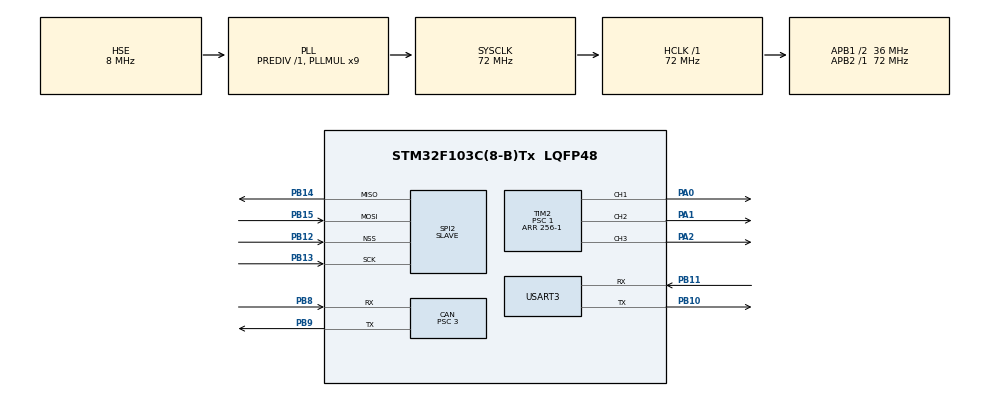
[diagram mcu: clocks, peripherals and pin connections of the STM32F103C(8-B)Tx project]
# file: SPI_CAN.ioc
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CAN.BS1=CAN_BS1_3TQ
CAN.BS2=CAN_BS2_8TQ
CAN.CalculateBaudRate=999999
CAN.CalculateTimeBit=1000
CAN.CalculateTimeQuantum=83.33333333333334
CAN.Prescaler=3
Dma.Request0=SPI2_RX
Dma.Request1=SPI2_TX
Dma.SPI2_RX.0.Direction=DMA_PERIPH_TO_MEMORY
Dma.SPI2_RX.0.Instance=DMA1_Channel4
Dma.SPI2_RX.0.MemDataAlignment=DMA_MDATAALIGN_BYTE
Dma.SPI2_RX.0.MemInc=DMA_MINC_ENABLE
Dma.SPI2_RX.0.Mode=DMA_CIRCULAR
Dma.SPI2_RX.0.PeriphDataAlignment=DMA_PDATAALIGN_BYTE
Dma.SPI2_RX.0.PeriphInc=DMA_PINC_DISABLE
Dma.SPI2_RX.0.Priority=DMA_PRIORITY_LOW
Dma.SPI2_TX.1.Direction=DMA_MEMORY_TO_PERIPH
Dma.SPI2_TX.1.Instance=DMA1_Channel5
Dma.SPI2_TX.1.MemDataAlignment=DMA_MDATAALIGN_BYTE
Dma.SPI2_TX.1.MemInc=DMA_MINC_ENABLE
Dma.SPI2_TX.1.Mode=DMA_CIRCULAR
Dma.SPI2_TX.1.PeriphDataAlignment=DMA_PDATAALIGN_BYTE
Dma.SPI2_TX.1.PeriphInc=DMA_PINC_DISABLE
Dma.SPI2_TX.1.Priority=DMA_PRIORITY_LOW
Mcu.Family=STM32F1
Mcu.Name=STM32F103C(8-B)Tx
Mcu.Package=LQFP48
NVIC.CAN1_RX1_IRQn=true\:0\:0\:false\:false\:true\:true\:true\:true
NVIC.DMA1_Channel4_IRQn=true\:0\:0\:false\:false\:true\:false\:true\:true
NVIC.DMA1_Channel5_IRQn=true\:0\:0\:false\:false\:true\:false\:true\:true
NVIC.PriorityGroup=NVIC_PRIORITYGROUP_4
NVIC.SPI2_IRQn=true\:0\:0\:false\:false\:true\:true\:true\:true
NVIC.USB_LP_CAN1_RX0_IRQn=true\:0\:0\:false\:false\:true\:true\:true\:true
PA0-WKUP.Signal=S_TIM2_CH1_ETR
PA1.Signal=S_TIM2_CH2
PA13.Mode=Serial_Wire
PA13.Signal=SYS_JTMS-SWDIO
PA14.Mode=Serial_Wire
PA14.Signal=SYS_JTCK-SWCLK
PA2.Signal=S_TIM2_CH3
PB10.Mode=Asynchronous
PB10.Signal=USART3_TX
PB11.Mode=Asynchronous
PB11.Signal=USART3_RX
PB12.Mode=NSS_Signal_Hard_Input
PB12.Signal=SPI2_NSS
PB13.Mode=Full_Duplex_Slave
PB13.Signal=SPI2_SCK
PB14.Mode=Full_Duplex_Slave
PB14.Signal=SPI2_MISO
PB15.Mode=Full_Duplex_Slave
PB15.Signal=SPI2_MOSI
PB8.Mode=CAN_Activate
PB8.Signal=CAN_RX
PB9.Mode=CAN_Activate
PB9.Signal=CAN_TX
PD0-OSC_IN.Mode=HSE-External-Oscillator
PD0-OSC_IN.Signal=RCC_OSC_IN
PD1-OSC_OUT.Mode=HSE-External-Oscillator
PD1-OSC_OUT.Signal=RCC_OSC_OUT
ProjectManager.HeapSize=0x200
ProjectManager.StackSize=0x400
ProjectManager.TargetToolchain=STM32CubeIDE
RCC.AHBFreq_Value=72000000
RCC.APB1CLKDivider=RCC_HCLK_DIV2
RCC.APB1Freq_Value=36000000
RCC.APB1TimFreq_Value=72000000
RCC.APB2Freq_Value=72000000
RCC.APB2TimFreq_Value=72000000
RCC.HCLKFreq_Value=72000000
RCC.PLLMUL=RCC_PLL_MUL9
RCC.PLLSourceVirtual=RCC_PLLSOURCE_HSE
RCC.SYSCLKFreq_VALUE=72000000
RCC.SYSCLKSource=RCC_SYSCLKSOURCE_PLLCLK
RCC.USBFreq_Value=72000000
SH.S_TIM2_CH1_ETR.0=TIM2_CH1,PWM Generation1 CH1
SH.S_TIM2_CH2.0=TIM2_CH2,PWM Generation2 CH2
SH.S_TIM2_CH3.0=TIM2_CH3,PWM Generation3 CH3
SPI2.CRCCalculation=SPI_CRCCALCULATION_DISABLE
SPI2.DataSize=SPI_DATASIZE_8BIT
SPI2.Direction=SPI_DIRECTION_2LINES
SPI2.Mode=SPI_MODE_SLAVE
SPI2.VirtualNSS=VM_NSSHARD
SPI2.VirtualType=VM_SLAVE
TIM2.AutoReloadPreload=TIM_AUTORELOAD_PRELOAD_DISABLE
TIM2.Channel-PWM\ Generation1\ CH1=TIM_CHANNEL_1
TIM2.Channel-PWM\ Generation2\ CH2=TIM_CHANNEL_2
TIM2.Channel-PWM\ Generation3\ CH3=TIM_CHANNEL_3
TIM2.OCMode_PWM-PWM\ Generation1\ CH1=TIM_OCMODE_PWM2
TIM2.OCMode_PWM-PWM\ Generation2\ CH2=TIM_OCMODE_PWM2
TIM2.OCMode_PWM-PWM\ Generation3\ CH3=TIM_OCMODE_PWM2
TIM2.Period=256-1
TIM2.Prescaler=1
USART3.VirtualMode=VM_ASYNC
VP_TIM2_VS_ClockSourceINT.Mode=Internal
board=custom

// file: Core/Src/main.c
/* USER CODE BEGIN Header */
/**
  ******************************************************************************
  * @file           : main.c
  * @brief          : Main program body
  ******************************************************************************
  * @attention
  *
  * Copyright (c) 2024 STMicroelectronics.
  * All rights reserved.
  *
  * This software is licensed under terms that can be found in the LICENSE file
  * in the root directory of this software component.
  * If no LICENSE file comes with this software, it is provided AS-IS.
  *
  ******************************************************************************
  */
/* USER CODE END Header */
#include "main.h"
#include "can.h"
#include "dma.h"
#include "spi.h"
#include "tim.h"
#include "usart.h"
#include "gpio.h"

/* USER CODE BEGIN Includes */
#include "common.h"
extern uint8_t spi_tx[BUFFER_SIZE], spi_rx[BUFFER_SIZE];

uint8_t err = HAL_OK;

/* USER CODE END Includes */

void SystemClock_Config(void);

int main(void)
{

  /* MCU Configuration--------------------------------------------------------*/

  /* Reset of all peripherals, Initializes the Flash interface and the Systick. */
  HAL_Init();

  /* Configure the system clock */
  SystemClock_Config();

  /* Initialize all configured peripherals */
  MX_GPIO_Init();
  MX_DMA_Init();
  MX_TIM2_Init();
  MX_SPI2_Init();
  MX_CAN_Init();
  MX_USART3_UART_Init();
  /* USER CODE BEGIN 2 */
  ledInit(&htim2);
  ledSet(20, 20, 40);
  CanInit(&hcan);

//  if((err = HAL_SPI_TransmitReceive_DMA(&hspi2, spi_tx, spi_rx, BUFFER_SIZE)) != HAL_OK) {
//    char fmt[50]; sprintf(fmt, "dma error(%d)\r\n", err);
//    HAL_UART_Transmit(&huart3, (uint8_t *)fmt, strlen(fmt), 0xffff);
//  }
  HAL_SPI_TransmitReceive_DMA(&hspi2, spi_tx, spi_rx, BUFFER_SIZE);
  /* USER CODE END 2 */

  /* Infinite loop */
  while (1)
  {

  }
}

void SystemClock_Config(void)
{
  RCC_OscInitTypeDef RCC_OscInitStruct = {0};
  RCC_ClkInitTypeDef RCC_ClkInitStruct = {0};

  /** Initializes the RCC Oscillators according to the specified parameters
  * in the RCC_OscInitTypeDef structure.
  */
  RCC_OscInitStruct.OscillatorType = RCC_OSCILLATORTYPE_HSE;
  RCC_OscInitStruct.HSEState = RCC_HSE_ON;
  RCC_OscInitStruct.HSEPredivValue = RCC_HSE_PREDIV_DIV1;
  RCC_OscInitStruct.HSIState = RCC_HSI_ON;
  RCC_OscInitStruct.PLL.PLLState = RCC_PLL_ON;
  RCC_OscInitStruct.PLL.PLLSource = RCC_PLLSOURCE_HSE;
  RCC_OscInitStruct.PLL.PLLMUL = RCC_PLL_MUL9;
  if (HAL_RCC_OscConfig(&RCC_OscInitStruct) != HAL_OK)
  {
    Error_Handler();
  }

  /** Initializes the CPU, AHB and APB buses clocks
  */
  RCC_ClkInitStruct.ClockType = RCC_CLOCKTYPE_HCLK|RCC_CLOCKTYPE_SYSCLK
                              |RCC_CLOCKTYPE_PCLK1|RCC_CLOCKTYPE_PCLK2;
  RCC_ClkInitStruct.SYSCLKSource = RCC_SYSCLKSOURCE_PLLCLK;
  RCC_ClkInitStruct.AHBCLKDivider = RCC_SYSCLK_DIV1;
  RCC_ClkInitStruct.APB1CLKDivider = RCC_HCLK_DIV2;
  RCC_ClkInitStruct.APB2CLKDivider = RCC_HCLK_DIV1;

  if (HAL_RCC_ClockConfig(&RCC_ClkInitStruct, FLASH_LATENCY_2) != HAL_OK)
  {
    Error_Handler();
  }
}

void Error_Handler(void)
{
  __disable_irq();
  while (1)
  {
  }
}
